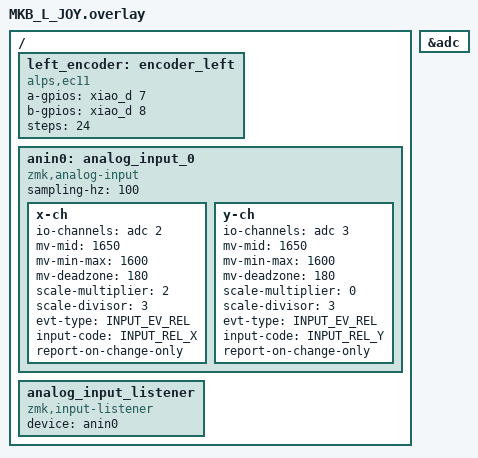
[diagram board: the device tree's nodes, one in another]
#include <zephyr/dt-bindings/input/input-event-codes.h>
#include <input/processors.dtsi>
#include <dt-bindings/zmk/input_transform.h>
#include <dt-bindings/zmk/keys.h>
#include "MKB_L_Base.dtsi"

&adc {
	status = "okay";
    // oversampling = <0>; 
};

/ {
   left_encoder: encoder_left {
      compatible = "alps,ec11";
      a-gpios = <&xiao_d 7 (GPIO_ACTIVE_HIGH | GPIO_PULL_UP)>;
      b-gpios = <&xiao_d 8 (GPIO_ACTIVE_HIGH | GPIO_PULL_UP)>;
      steps = <24>;
      status = "disabled";
   };

    anin0: analog_input_0 {
        compatible = "zmk,analog-input";
        sampling-hz = <100>;
        x-ch {
            io-channels = <&adc 2>;
            mv-mid = <1650>;
            mv-min-max = <1600>;
            mv-deadzone = <180>;
            scale-multiplier = <2>;
            scale-divisor = <3>;
            // invert;
            evt-type = <INPUT_EV_REL>;
            input-code = <INPUT_REL_X>;
            report-on-change-only;
        };
        y-ch {
            io-channels = <&adc 3>;
            mv-mid = <1650>;
            mv-min-max = <1600>;
            mv-deadzone = <180>;
            scale-multiplier = <0>;
            scale-divisor = <3>;
            // invert;
            evt-type = <INPUT_EV_REL>;
            input-code = <INPUT_REL_Y>;
            report-on-change-only;
        };
    };
    
    analog_input_listener {
        status = "okay";
        compatible = "zmk,input-listener";
        device = <&anin0>;
        // input-processors = <&zip_xy_to_scroll_mapper>;
        
        // scroll {
        //     layers = <0>;
        //     input-processors = <&zip_xy_to_scroll_mapper>;
        // };
    };
};

&left_encoder {
    status = "okay";
};
